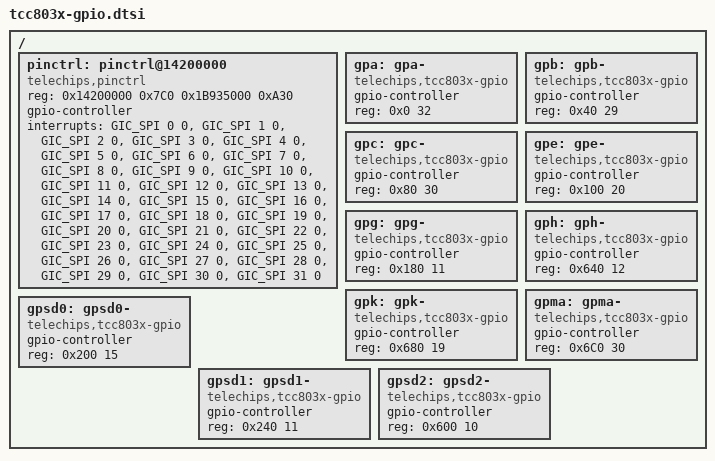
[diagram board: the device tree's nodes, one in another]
// SPDX-License-Identifier: (GPL-2.0-or-later OR MIT)
/*
 * Copyright (C) 2023 Telechips Inc.
 */

#include <dt-bindings/interrupt-controller/arm-gic.h>
#include <dt-bindings/gpio/gpio.h>

/ {
	pinctrl: pinctrl@14200000 {
		compatible = "telechips,pinctrl";
		reg = <0x14200000 0x7C0 0x1B935000 0xA30>; /* gpio, pmgpio */
		gpio-controller;
		#address-cells = <1>;
		#size-cells = <0>;
		#gpio-cells = <3>;
		interrupts = <GIC_SPI 0 0>,
			     <GIC_SPI 1 0>,
			     <GIC_SPI 2 0>,
			     <GIC_SPI 3 0>,
			     <GIC_SPI 4 0>,
			     <GIC_SPI 5 0>,
			     <GIC_SPI 6 0>,
			     <GIC_SPI 7 0>,
			     <GIC_SPI 8 0>,
			     <GIC_SPI 9 0>,
			     <GIC_SPI 10 0>,
			     <GIC_SPI 11 0>,
			     <GIC_SPI 12 0>,
			     <GIC_SPI 13 0>,
			     <GIC_SPI 14 0>,
			     <GIC_SPI 15 0>,
			     <GIC_SPI 16 0>,
			     <GIC_SPI 17 0>,
			     <GIC_SPI 18 0>,
			     <GIC_SPI 19 0>,
			     <GIC_SPI 20 0>,
			     <GIC_SPI 21 0>,
			     <GIC_SPI 22 0>,
			     <GIC_SPI 23 0>,
			     <GIC_SPI 24 0>,
			     <GIC_SPI 25 0>,
			     <GIC_SPI 26 0>,
			     <GIC_SPI 27 0>,
			     <GIC_SPI 28 0>,
			     <GIC_SPI 29 0>,
			     <GIC_SPI 30 0>,
			     <GIC_SPI 31 0>;
	};

	gpa: gpa- {
		compatible = "telechips,tcc803x-gpio";
		gpio-controller;
		#gpio-cells = <2>;
		reg = <0x0 32>;
	};

	gpb: gpb- {
		compatible = "telechips,tcc803x-gpio";
		gpio-controller;
		#gpio-cells = <2>;
		reg = <0x40 29>;
	};

	gpc: gpc- {
		compatible = "telechips,tcc803x-gpio";
		gpio-controller;
		#gpio-cells = <2>;
		reg = <0x80 30>;
	};

	gpe: gpe- {
		compatible = "telechips,tcc803x-gpio";
		gpio-controller;
		#gpio-cells = <2>;
		reg = <0x100 20>;
	};

	gpg: gpg- {
		compatible = "telechips,tcc803x-gpio";
		gpio-controller;
		#gpio-cells = <2>;
		reg = <0x180 11>;
	};

	gph: gph- {
		compatible = "telechips,tcc803x-gpio";
		gpio-controller;
		#gpio-cells = <2>;
		reg = <0x640 12>;
	};

	gpk: gpk- {
		compatible = "telechips,tcc803x-gpio";
		gpio-controller;
		#gpio-cells = <2>;
		reg = <0x680 19>;
	};

	gpma: gpma- {
		compatible = "telechips,tcc803x-gpio";
		gpio-controller;
		#gpio-cells = <2>;
		reg = <0x6C0 30>;
	};

	gpsd0: gpsd0- {
		compatible = "telechips,tcc803x-gpio";
		gpio-controller;
		#gpio-cells = <2>;
		reg = <0x200 15>;
	};

	gpsd1: gpsd1- {
		compatible = "telechips,tcc803x-gpio";
		gpio-controller;
		#gpio-cells = <2>;
		reg = <0x240 11>;
	};

	gpsd2: gpsd2- {
		compatible = "telechips,tcc803x-gpio";
		gpio-controller;
		#gpio-cells = <2>;
		reg = <0x600 10>;
	};
};
